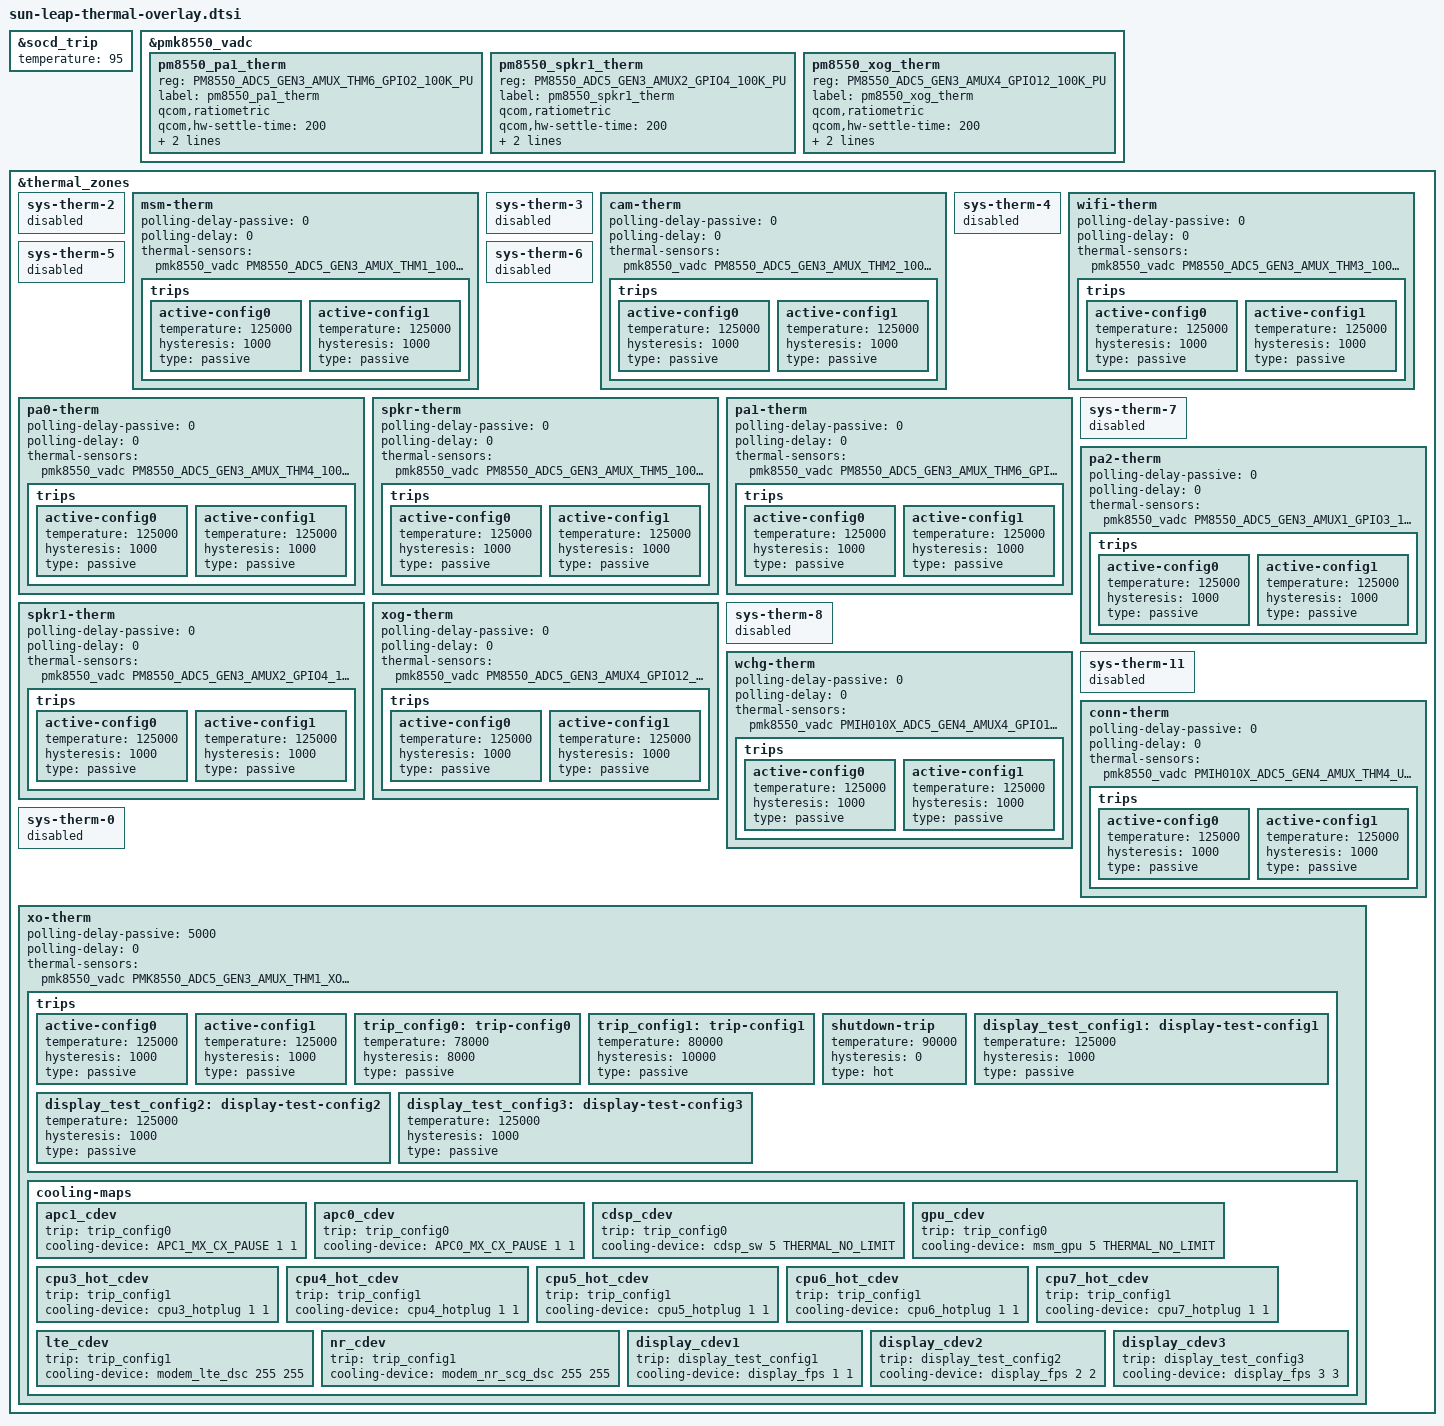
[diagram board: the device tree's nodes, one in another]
#include "moto_therm_sys_temp.dtsi"

&socd_trip {
    temperature = <95>;
};

&pmk8550_vadc {
	pm8550_pa1_therm {
		reg = <PM8550_ADC5_GEN3_AMUX_THM6_GPIO2_100K_PU>;
		label = "pm8550_pa1_therm";
		qcom,ratiometric;
		qcom,hw-settle-time = <200>;
		qcom,pre-scaling = <1 1>;
		qcom,adc-tm-type = <1>;
	};

	pm8550_spkr1_therm {
		reg = <PM8550_ADC5_GEN3_AMUX2_GPIO4_100K_PU>;
		label = "pm8550_spkr1_therm";
		qcom,ratiometric;
		qcom,hw-settle-time = <200>;
		qcom,pre-scaling = <1 1>;
		qcom,adc-tm-type = <1>;
	};

	pm8550_xog_therm {
		reg = <PM8550_ADC5_GEN3_AMUX4_GPIO12_100K_PU>;
		label = "pm8550_xog_therm";
		qcom,ratiometric;
		qcom,hw-settle-time = <200>;
		qcom,pre-scaling = <1 1>;
		qcom,adc-tm-type = <1>;
	};

};

/delete-node/ &trip_config0;
/delete-node/ &trip_config1;
/delete-node/ &display_test_config1;
/delete-node/ &display_test_config2;
/delete-node/ &display_test_config3;

&thermal_zones {
	sys-therm-2 {
		status = "disabled";
	};
	msm-therm {
		polling-delay-passive = <0>;
		polling-delay = <0>;
		thermal-sensors = <&pmk8550_vadc PM8550_ADC5_GEN3_AMUX_THM1_100K_PU>;
		trips {
			active-config0 {
				temperature = <125000>;
				hysteresis = <1000>;
				type = "passive";
			};

			active-config1 {
				temperature = <125000>;
				hysteresis = <1000>;
				type = "passive";
			};
		};
	};

	sys-therm-3 {
		status = "disabled";
	};
	cam-therm {
		polling-delay-passive = <0>;
		polling-delay = <0>;
		thermal-sensors = <&pmk8550_vadc PM8550_ADC5_GEN3_AMUX_THM2_100K_PU>;
		trips {
			active-config0 {
				temperature = <125000>;
				hysteresis = <1000>;
				type = "passive";
			};

			active-config1 {
				temperature = <125000>;
				hysteresis = <1000>;
				type = "passive";
			};
		};
	};

	sys-therm-4 {
		status = "disabled";
	};
	wifi-therm {
		polling-delay-passive = <0>;
		polling-delay = <0>;
		thermal-sensors = <&pmk8550_vadc PM8550_ADC5_GEN3_AMUX_THM3_100K_PU>;
		trips {
			active-config0 {
				temperature = <125000>;
				hysteresis = <1000>;
				type = "passive";
			};

			active-config1 {
				temperature = <125000>;
				hysteresis = <1000>;
				type = "passive";
			};
		};
	};

	sys-therm-5 {
		status = "disabled";
	};
	pa0-therm {
		polling-delay-passive = <0>;
		polling-delay = <0>;
		thermal-sensors = <&pmk8550_vadc PM8550_ADC5_GEN3_AMUX_THM4_100K_PU>;
		trips {
			active-config0 {
				temperature = <125000>;
				hysteresis = <1000>;
				type = "passive";
			};

			active-config1 {
				temperature = <125000>;
				hysteresis = <1000>;
				type = "passive";
			};
		};
	};

	sys-therm-6 {
		status = "disabled";
	};
	spkr-therm {
		polling-delay-passive = <0>;
		polling-delay = <0>;
		thermal-sensors = <&pmk8550_vadc PM8550_ADC5_GEN3_AMUX_THM5_100K_PU>;
		trips {
			active-config0 {
				temperature = <125000>;
				hysteresis = <1000>;
				type = "passive";
			};

			active-config1 {
				temperature = <125000>;
				hysteresis = <1000>;
				type = "passive";
			};
		};
	};

	pa1-therm {
		polling-delay-passive = <0>;
		polling-delay = <0>;
		thermal-sensors = <&pmk8550_vadc PM8550_ADC5_GEN3_AMUX_THM6_GPIO2_100K_PU>;
		trips {
			active-config0 {
				temperature = <125000>;
				hysteresis = <1000>;
				type = "passive";
			};

			active-config1 {
				temperature = <125000>;
				hysteresis = <1000>;
				type = "passive";
			};
		};
	};

	sys-therm-7 {
		status = "disabled";
	};
	pa2-therm {
		polling-delay-passive = <0>;
		polling-delay = <0>;
		thermal-sensors = <&pmk8550_vadc PM8550_ADC5_GEN3_AMUX1_GPIO3_100K_PU>;
		trips {
			active-config0 {
				temperature = <125000>;
				hysteresis = <1000>;
				type = "passive";
			};

			active-config1 {
				temperature = <125000>;
				hysteresis = <1000>;
				type = "passive";
			};
		};
	};

	spkr1-therm {
		polling-delay-passive = <0>;
		polling-delay = <0>;
		thermal-sensors = <&pmk8550_vadc PM8550_ADC5_GEN3_AMUX2_GPIO4_100K_PU>;
		trips {
			active-config0 {
				temperature = <125000>;
				hysteresis = <1000>;
				type = "passive";
			};

			active-config1 {
				temperature = <125000>;
				hysteresis = <1000>;
				type = "passive";
			};
		};
	};

	xog-therm {
		polling-delay-passive = <0>;
		polling-delay = <0>;
		thermal-sensors = <&pmk8550_vadc PM8550_ADC5_GEN3_AMUX4_GPIO12_100K_PU>;
		trips {
			active-config0 {
				temperature = <125000>;
				hysteresis = <1000>;
				type = "passive";
			};

			active-config1 {
				temperature = <125000>;
				hysteresis = <1000>;
				type = "passive";
			};
		};
	};

	sys-therm-8 {
		status = "disabled";
	};
	wchg-therm {
		polling-delay-passive = <0>;
		polling-delay = <0>;
		thermal-sensors = <&pmk8550_vadc PMIH010X_ADC5_GEN4_AMUX4_GPIO12_100K_PU>;
		trips {
			active-config0 {
				temperature = <125000>;
				hysteresis = <1000>;
				type = "passive";
			};

			active-config1 {
				temperature = <125000>;
				hysteresis = <1000>;
				type = "passive";
			};
		};
	};

	sys-therm-11 {
		status = "disabled";
	};
	conn-therm {
		polling-delay-passive = <0>;
		polling-delay = <0>;
		thermal-sensors = <&pmk8550_vadc PMIH010X_ADC5_GEN4_AMUX_THM4_USB_THERM_100K_PU>;
		trips {
			active-config0 {
				temperature = <125000>;
				hysteresis = <1000>;
				type = "passive";
			};

			active-config1 {
				temperature = <125000>;
				hysteresis = <1000>;
				type = "passive";
			};
		};
	};

	/* Only sys-therm-0 renamed xo-therm*/
	sys-therm-0 {
		status = "disabled";
	};
	xo-therm {
		polling-delay-passive = <5000>;
		polling-delay = <0>;
		thermal-sensors = <&pmk8550_vadc PMK8550_ADC5_GEN3_AMUX_THM1_XO_THERM_100K_PU>;
		trips {
			active-config0 {
				temperature = <125000>;
				hysteresis = <1000>;
				type = "passive";
			};

			active-config1 {
				temperature = <125000>;
				hysteresis = <1000>;
				type = "passive";
			};

			trip_config0: trip-config0 {
				temperature = <78000>;
				hysteresis = <8000>;
				type = "passive";
			};

			trip_config1: trip-config1 {
				temperature = <80000>;
				hysteresis = <10000>;
				type = "passive";
			};

			shutdown-trip {
				temperature = <90000>;
				hysteresis = <0>;
				type = "hot";
			};

			display_test_config1: display-test-config1 {
				temperature = <125000>;
				hysteresis = <1000>;
				type = "passive";
			};

			display_test_config2: display-test-config2 {
				temperature = <125000>;
				hysteresis = <1000>;
				type = "passive";
			};

			display_test_config3: display-test-config3 {
				temperature = <125000>;
				hysteresis = <1000>;
				type = "passive";
			};
		};
		cooling-maps {
			apc1_cdev {
				trip = <&trip_config0>;
				cooling-device = <&APC1_MX_CX_PAUSE 1 1>;
			};

			apc0_cdev {
				trip = <&trip_config0>;
				cooling-device = <&APC0_MX_CX_PAUSE 1 1>;
			};

			cdsp_cdev {
				trip = <&trip_config0>;
				cooling-device = <&cdsp_sw 5 THERMAL_NO_LIMIT>;
			};

			gpu_cdev {
				trip = <&trip_config0>;
				cooling-device = <&msm_gpu 5 THERMAL_NO_LIMIT>;
			};

			cpu3_hot_cdev {
				trip = <&trip_config1>;
				cooling-device = <&cpu3_hotplug 1 1>;
			};

			cpu4_hot_cdev {
				trip = <&trip_config1>;
				cooling-device = <&cpu4_hotplug 1 1>;
			};

			cpu5_hot_cdev {
				trip = <&trip_config1>;
				cooling-device = <&cpu5_hotplug 1 1>;
			};

			cpu6_hot_cdev {
				trip = <&trip_config1>;
				cooling-device = <&cpu6_hotplug 1 1>;
			};

			cpu7_hot_cdev {
				trip = <&trip_config1>;
				cooling-device = <&cpu7_hotplug 1 1>;
			};

			lte_cdev {
				trip = <&trip_config1>;
				cooling-device = <&modem_lte_dsc 255 255>;
			};

			nr_cdev {
				trip = <&trip_config1>;
				cooling-device = <&modem_nr_scg_dsc 255 255>;
			};

			display_cdev1 {
				trip = <&display_test_config1>;
				cooling-device = <&display_fps 1 1>;
			};

			display_cdev2 {
				trip = <&display_test_config2>;
				cooling-device = <&display_fps 2 2>;
			};

			display_cdev3 {
				trip = <&display_test_config3>;
				cooling-device = <&display_fps 3 3>;
			};
		};
	};
};
